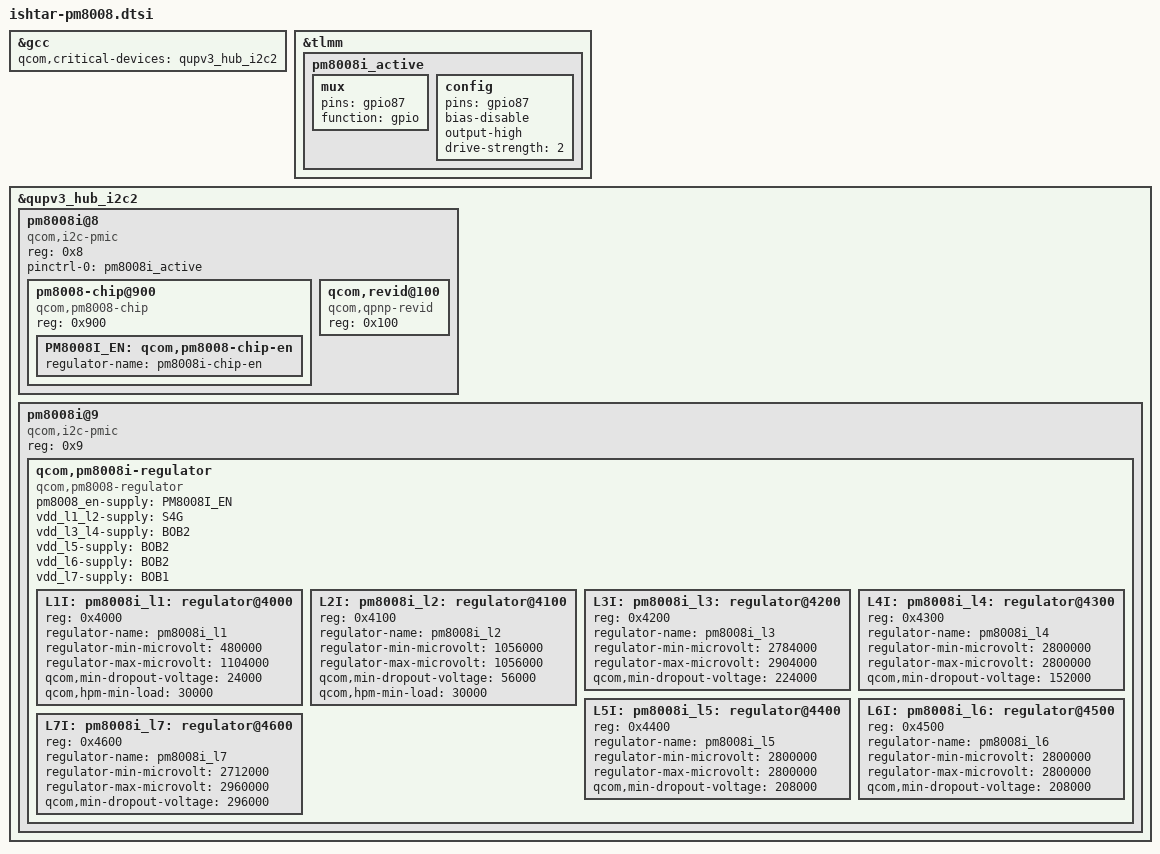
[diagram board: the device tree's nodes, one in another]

&gcc {
	qcom,critical-devices = <&qupv3_hub_i2c2>;
};

&tlmm {

	pm8008i_active: pm8008i_active {
		mux {
			pins = "gpio87";
			function = "gpio";
		};

		config {
			pins = "gpio87";
			bias-disable;
			output-high;
			drive-strength = <2>;
		};
	};
};

&qupv3_hub_i2c2 {
	#address-cells = <1>;
	#size-cells = <0>;
	status = "ok";

	pm8008i@8 {
		compatible = "qcom,i2c-pmic";
		reg = <0x8>;
		#address-cells = <1>;
		#size-cells = <0>;

		pinctrl-names = "default";
		pinctrl-0 = <&pm8008i_active>;

		pm8008-chip@900 {
			compatible = "qcom,pm8008-chip";
			reg = <0x900>;

			PM8008I_EN: qcom,pm8008-chip-en {
				regulator-name = "pm8008i-chip-en";
			};
		};

		qcom,revid@100 {
			compatible = "qcom,qpnp-revid";
			reg = <0x100>;
		};
	};

	pm8008i@9 {
		compatible = "qcom,i2c-pmic";
		reg = <0x9>;
		#address-cells = <1>;
		#size-cells = <0>;

		qcom,pm8008i-regulator {
			compatible = "qcom,pm8008-regulator";
			#address-cells = <1>;
			#size-cells = <0>;

			pm8008_en-supply = <&PM8008I_EN>;
			vdd_l1_l2-supply = <&S4G>;
			vdd_l3_l4-supply = <&BOB2>;
			vdd_l5-supply = <&BOB2>;
			vdd_l6-supply = <&BOB2>;
			vdd_l7-supply = <&BOB1>;

			L1I: pm8008i_l1: regulator@4000 {
				reg = <0x4000>;
				regulator-name = "pm8008i_l1";
				regulator-min-microvolt = <480000>;
				regulator-max-microvolt = <1104000>;
				qcom,min-dropout-voltage = <24000>;
				qcom,hpm-min-load = <30000>;
			};

			L2I: pm8008i_l2: regulator@4100 {
				reg = <0x4100>;
				regulator-name = "pm8008i_l2";
				regulator-min-microvolt = <1056000>;
				regulator-max-microvolt = <1056000>;
				qcom,min-dropout-voltage = <56000>;
				qcom,hpm-min-load = <30000>;
			};

			L3I: pm8008i_l3: regulator@4200 {
				reg = <0x4200>;
				regulator-name = "pm8008i_l3";
				regulator-min-microvolt = <2784000>;
				regulator-max-microvolt = <2904000>;
				qcom,min-dropout-voltage = <224000>;
			};

			L4I: pm8008i_l4: regulator@4300 {
				reg = <0x4300>;
				regulator-name = "pm8008i_l4";
				regulator-min-microvolt = <2800000>;
				regulator-max-microvolt = <2800000>;
				qcom,min-dropout-voltage = <152000>;
			};

			L5I: pm8008i_l5: regulator@4400 {
				reg = <0x4400>;
				regulator-name = "pm8008i_l5";
				regulator-min-microvolt = <2800000>;
				regulator-max-microvolt = <2800000>;
				qcom,min-dropout-voltage = <208000>;
			};

			L6I: pm8008i_l6: regulator@4500 {
				reg = <0x4500>;
				regulator-name = "pm8008i_l6";
				regulator-min-microvolt = <2800000>;
				regulator-max-microvolt = <2800000>;
				qcom,min-dropout-voltage = <208000>;
			};

			L7I: pm8008i_l7: regulator@4600 {
				reg = <0x4600>;
				regulator-name = "pm8008i_l7";
				regulator-min-microvolt = <2712000>;
				regulator-max-microvolt = <2960000>;
				qcom,min-dropout-voltage = <296000>;
			};
		};
	};

	/delete-node/ pm8008j@c;
	/delete-node/ pm8008j@d;
};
